# f29h85x_secap_handler_regs register map
Vendor: Texas Instruments
Peripheral module from a debugger description file (folder C29).
Registers are 32-bit, read-only, no defined reset value unless marked. A register's access mark holds for its fields unless they carry their own. Offsets are as the file gives them; lines under a group give offsets from that group; [hi:lo] are bit positions; {n}, {i} and the like mark numbered series; 'fields as' and 'values as' point back to an identical list; <NAME> marks a mode.

## SECAP_HANDLER_REGS — SECAP HANDLER Registers
0x00 PASSWORD_ID
  [3:0] ID
{0x0+4i} PASSWORD{i} (i=1..4)
  [31:0] PASSWORD — SSU Password{i} register
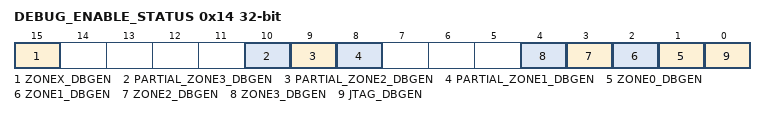
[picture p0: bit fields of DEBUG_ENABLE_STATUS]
0x14 DEBUG_ENABLE_STATUS — Debug status register
  [15] ZONEX_DBGEN — ZoneX Debug enable
  [10] PARTIAL_ZONE3_DBGEN — Partial Zone3 Debug enable
  [9] PARTIAL_ZONE2_DBGEN — Partial Zone2 Debug enable
  [8] PARTIAL_ZONE1_DBGEN — Partial Zone1 Debug enable
  [n+1] ZONE{n}_DBGEN (n=0..3) — Zone{n+1} Full Debug enable
  [0] JTAG_DBGEN — JTAG Full Debug enable
{0x7C+4i} TEST_PASSWORD{i} (i=1..4)
  [31:0] PASSWORD — HSM Test Password{i} Register
0x100 DBG2CPU1_CHR — Debugger to CPU1/SSU challenge response
  [31:0] MSG — Challenge response message
0x104 CPU12DBG_CHR rw — CPU1/SSU to Debugger challenge response
  [31:0] MSG — Challenge response message
0x108 DBG2CPU1_HS — Debugger to CPU1/SSU Handshake
  [31:0] DAT — Handshaking message
0x10C CPU12DBG_HS rw — CPU1/SSU to Debugger Handshake
  [31:0] DAT — Handshaking message
0x110 DBG2CPU1_INT_FLG — Debugger to CPU1 interrupt flag
  [0] INT — Debugger to CPU Interrupt flag
0x114 DBG2CPU1_INT_FLG_SET — Debugger to CPU1 interrupt set
  [0] INT — Debugger to CPU Interrupt set
0x118 DBG2CPU1_INT_FLG_CLR rw — Debugger to CPU1 interrupt clear
  [0] INT — Debugger to CPU Interrupt flag clear
0x204 SSU_DBG_STATUS — Read only SSU DBG Status
  [31:0] MSG — SSU to debugger Status register
0x208 HSM_DBG_STATUS — Read only HSM DBG Status
  [31:0] MSG — HSM to debugger Status register
0x20C CTL_DBG_STATUS — Read only CTL DBG Status
  [31:0] MSG — CTL to debugger Status register
{0x210+4i} GEN_DBG_STATUS{i} (i=0..3) — Read only GEN DBG Status{i}
  [31:0] MSG — GEN to debugger Status register
{0x220+4i} GEN_DBG_STICKY_STATUS{i} (i=0..3) — Read only GEN DBG_STICKY Status{i}
  [31:0] MSG — GEN to debugger Status sitcky register
{0x230+4i} GEN_DBG_STICKY_CLR{i} (i=0..3) — Write only GEN_DBG_STICKY clear register{i}
  [31:0] STATS_CLR — GEN to debugger Status clear register
0x240 C29_DBG_RX_ADDR — RX Data Write Address
  [31:1] ADDRESS — Rx Bus Address register
0x244 JTAG_GEN — jtag general purpose register
  [31:0] MSG — JTAG general purpose message
